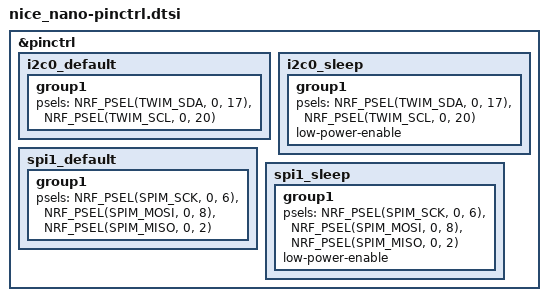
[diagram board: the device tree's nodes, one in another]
/*
 * Pin control configuration for nice!nano v2
 *
 * I2C0: SDA=P0.17, SCL=P0.20
 * SPI1: SCK=P0.06, MOSI=P0.08, MISO=P0.02
 *
 * SPDX-License-Identifier: MIT
 */

&pinctrl {
    i2c0_default: i2c0_default {
        group1 {
            psels = <NRF_PSEL(TWIM_SDA, 0, 17)>,
                <NRF_PSEL(TWIM_SCL, 0, 20)>;
        };
    };

    i2c0_sleep: i2c0_sleep {
        group1 {
            psels = <NRF_PSEL(TWIM_SDA, 0, 17)>,
                <NRF_PSEL(TWIM_SCL, 0, 20)>;
            low-power-enable;
        };
    };

    spi1_default: spi1_default {
        group1 {
            psels = <NRF_PSEL(SPIM_SCK, 0, 6)>,
                <NRF_PSEL(SPIM_MOSI, 0, 8)>,
                <NRF_PSEL(SPIM_MISO, 0, 2)>;
        };
    };

    spi1_sleep: spi1_sleep {
        group1 {
            psels = <NRF_PSEL(SPIM_SCK, 0, 6)>,
                <NRF_PSEL(SPIM_MOSI, 0, 8)>,
                <NRF_PSEL(SPIM_MISO, 0, 2)>;
            low-power-enable;
        };
    };
};
